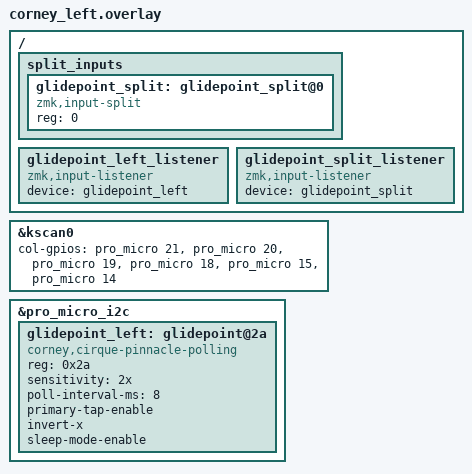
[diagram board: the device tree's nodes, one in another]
#include "corney.dtsi"

&kscan0 {
    col-gpios
        = <&pro_micro 21 GPIO_ACTIVE_HIGH>
        , <&pro_micro 20 GPIO_ACTIVE_HIGH>
        , <&pro_micro 19 GPIO_ACTIVE_HIGH>
        , <&pro_micro 18 GPIO_ACTIVE_HIGH>
        , <&pro_micro 15 GPIO_ACTIVE_HIGH>
        , <&pro_micro 14 GPIO_ACTIVE_HIGH>
        ;
};

&pro_micro_i2c {
    status = "okay";

    glidepoint_left: glidepoint@2a {
        compatible = "corney,cirque-pinnacle-polling";
        reg = <0x2a>;
        status = "okay";

        sensitivity = "2x";
        poll-interval-ms = <8>;
        primary-tap-enable;
        invert-x;
        sleep-mode-enable;
    };
};

/ {
    split_inputs {
        #address-cells = <1>;
        #size-cells = <0>;

        glidepoint_split: glidepoint_split@0 {
            compatible = "zmk,input-split";
            reg = <0>;
        };
    };

    glidepoint_left_listener {
        compatible = "zmk,input-listener";
        device = <&glidepoint_left>;
    };

    glidepoint_split_listener {
        compatible = "zmk,input-listener";
        device = <&glidepoint_split>;
    };
};
